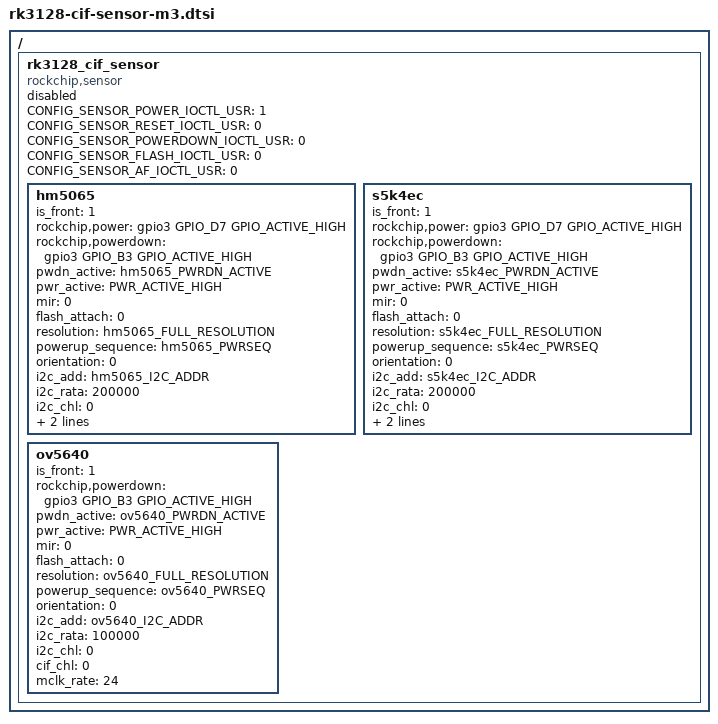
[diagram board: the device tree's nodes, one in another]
#include "../../mach-rockchip/rk_camera_sensor_info.h"
/{
	rk3128_cif_sensor: rk3128_cif_sensor{
			compatible = "rockchip,sensor";
			status = "disabled";
			CONFIG_SENSOR_POWER_IOCTL_USR 		= <1>;
			CONFIG_SENSOR_RESET_IOCTL_USR 		= <0>;
			CONFIG_SENSOR_POWERDOWN_IOCTL_USR	= <0>;
			CONFIG_SENSOR_FLASH_IOCTL_USR	  	= <0>;
			CONFIG_SENSOR_AF_IOCTL_USR	   		= <0>;

     hm5065{
            is_front = <1>;
            rockchip,power = <&gpio3 GPIO_D7 GPIO_ACTIVE_HIGH>;
            rockchip,powerdown = <&gpio3 GPIO_B3 GPIO_ACTIVE_HIGH>;
            pwdn_active = <hm5065_PWRDN_ACTIVE>;
            pwr_active = <PWR_ACTIVE_HIGH>;
            mir = <0>;
            flash_attach = <0>;
            resolution = <hm5065_FULL_RESOLUTION>;
            powerup_sequence = <hm5065_PWRSEQ>;
            orientation = <0>;
            i2c_add = <hm5065_I2C_ADDR>;
            i2c_rata = <200000>;
            i2c_chl = <0>;
            cif_chl = <0>;
            mclk_rate = <24>;
        };


     s5k4ec{
            is_front = <1>;
            rockchip,power = <&gpio3 GPIO_D7 GPIO_ACTIVE_HIGH>;
            rockchip,powerdown = <&gpio3 GPIO_B3 GPIO_ACTIVE_HIGH>;
            pwdn_active = <s5k4ec_PWRDN_ACTIVE>;
            pwr_active = <PWR_ACTIVE_HIGH>;
            mir = <0>;
            flash_attach = <0>;
            resolution = <s5k4ec_FULL_RESOLUTION>;
            powerup_sequence = <s5k4ec_PWRSEQ>;
            orientation = <0>;
            i2c_add = <s5k4ec_I2C_ADDR>;
            i2c_rata = <200000>;
            i2c_chl = <0>;
            cif_chl = <0>;
            mclk_rate = <24>;
        };
	ov5640{
            is_front = <1>;
         //  rockchip,power = <&gpio3 GPIO_D7 GPIO_ACTIVE_HIGH>;
            rockchip,powerdown = <&gpio3 GPIO_B3 GPIO_ACTIVE_HIGH>;
	  //  rockchip,powerdown_pmu = "rk818_ldo4";
	   // rockchip,powerdown_pmu_voltage = <2800000>;
	   // rockchip,power_pmu_name1 = "rk818_ldo8";
	   // rockchip,powerdown_pmu_voltage1 = <1800000>;
            pwdn_active = <ov5640_PWRDN_ACTIVE>;
            pwr_active = <PWR_ACTIVE_HIGH>;
            mir = <0>;
            flash_attach = <0>;
            resolution = <ov5640_FULL_RESOLUTION>;
            powerup_sequence = <ov5640_PWRSEQ>;
            orientation = <0>;
            i2c_add = <ov5640_I2C_ADDR>;
            i2c_rata = <100000>;
            i2c_chl = <0>;
            cif_chl = <0>;
            mclk_rate = <24>;
        };
	};
};

